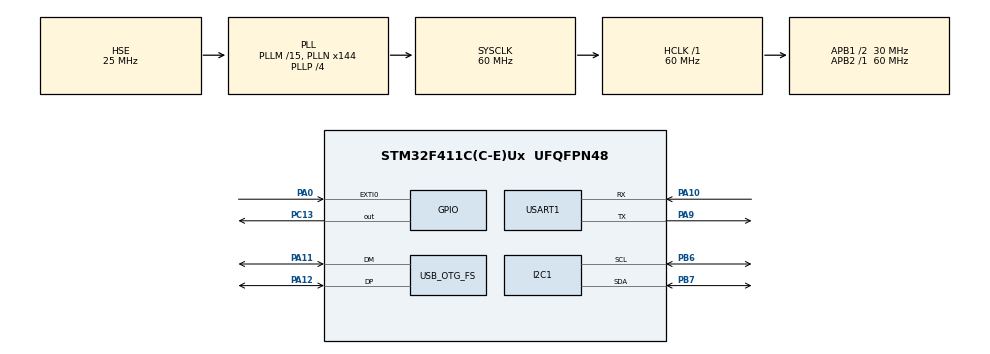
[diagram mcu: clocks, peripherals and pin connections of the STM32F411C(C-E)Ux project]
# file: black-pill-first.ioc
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FREERTOS.Tasks01=defaultTask,24,128,StartDefaultTask,Default,NULL,Dynamic,NULL,NULL
Mcu.Family=STM32F4
Mcu.Name=STM32F411C(C-E)Ux
Mcu.Package=UFQFPN48
NVIC.OTG_FS_IRQn=true\:5\:0\:false\:false\:true\:true\:false\:true\:true
NVIC.PriorityGroup=NVIC_PRIORITYGROUP_4
NVIC.TIM1_UP_TIM10_IRQn=true\:15\:0\:false\:false\:true\:false\:false\:true\:true
NVIC.TimeBase=TIM1_UP_TIM10_IRQn
NVIC.TimeBaseIP=TIM1
PA0-WKUP.GPIO_ModeDefaultEXTI=GPIO_MODE_IT_RISING_FALLING
PA0-WKUP.GPIO_PuPd=GPIO_NOPULL
PA0-WKUP.Signal=GPXTI0
PA10.Mode=Asynchronous
PA10.Signal=USART1_RX
PA11.Mode=Device_Only
PA11.Signal=USB_OTG_FS_DM
PA12.Mode=Device_Only
PA12.Signal=USB_OTG_FS_DP
PA13.Mode=Serial_Wire
PA13.Signal=SYS_JTMS-SWDIO
PA14.Mode=Serial_Wire
PA14.Signal=SYS_JTCK-SWCLK
PA9.Mode=Asynchronous
PA9.Signal=USART1_TX
PB6.Mode=I2C
PB6.Signal=I2C1_SCL
PB7.Mode=I2C
PB7.Signal=I2C1_SDA
PC13-ANTI_TAMP.Signal=GPIO_Output
PH0\ -\ OSC_IN.Mode=HSE-External-Oscillator
PH0\ -\ OSC_IN.Signal=RCC_OSC_IN
PH1\ -\ OSC_OUT.Mode=HSE-External-Oscillator
PH1\ -\ OSC_OUT.Signal=RCC_OSC_OUT
ProjectManager.HeapSize=0x200
ProjectManager.StackSize=0x400
ProjectManager.TargetToolchain=CMake
RCC.48MHZClocksFreq_Value=48000000
RCC.AHBFreq_Value=60000000
RCC.APB1CLKDivider=RCC_HCLK_DIV2
RCC.APB1Freq_Value=30000000
RCC.APB1TimFreq_Value=60000000
RCC.APB2Freq_Value=60000000
RCC.APB2TimFreq_Value=60000000
RCC.CortexFreq_Value=60000000
RCC.HCLKFreq_Value=60000000
RCC.HSE_VALUE=25000000
RCC.HSI_VALUE=16000000
RCC.LSE_VALUE=32768
RCC.PLLM=15
RCC.PLLN=144
RCC.PLLP=RCC_PLLP_DIV4
RCC.PLLQ=5
RCC.SYSCLKFreq_VALUE=60000000
RCC.SYSCLKSource=RCC_SYSCLKSOURCE_PLLCLK
RCC.VCOOutputFreq_Value=240000000
USART1.VirtualMode=VM_ASYNC
USB_DEVICE.CLASS_NAME_FS=CDC
USB_DEVICE.VirtualMode=Cdc
USB_DEVICE.VirtualModeFS=Cdc_FS
USB_OTG_FS.VirtualMode=Device_Only
VP_FREERTOS_VS_CMSIS_V2.Mode=CMSIS_V2
VP_SYS_VS_tim1.Mode=TIM1
VP_USB_DEVICE_VS_USB_DEVICE_CDC_FS.Mode=CDC_FS
board=custom

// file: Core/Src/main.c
/* USER CODE BEGIN Header */
/**
  ******************************************************************************
  * @file           : main.c
  * @brief          : Main program body
  ******************************************************************************
  * @attention
  *
  * Copyright (c) 2026 STMicroelectronics.
  * All rights reserved.
  *
  * This software is licensed under terms that can be found in the LICENSE file
  * in the root directory of this software component.
  * If no LICENSE file comes with this software, it is provided AS-IS.
  *
  ******************************************************************************
  */
/* USER CODE END Header */
#include "main.h"
#include "cmsis_os.h"
#include "i2c.h"
#include "usart.h"
#include "usb_device.h"
#include "gpio.h"

/* USER CODE BEGIN Includes */
#include "app.h"
#include "usbd_cdc_if.h"
#include <string.h>
#include <stdio.h>
/* USER CODE END Includes */

void SystemClock_Config(void);
void MX_FREERTOS_Init(void);

/* USER CODE BEGIN 0 */

int _write(int file, char *ptr, int len) {
    CDC_Transmit_FS((uint8_t*)ptr, len);
    return len;
}

/* USER CODE END 0 */

int main(void)
{

  /* MCU Configuration--------------------------------------------------------*/

  /* Reset of all peripherals, Initializes the Flash interface and the Systick. */
  HAL_Init();

  /* Configure the system clock */
  SystemClock_Config();

  /* Initialize all configured peripherals */
  MX_GPIO_Init();
  MX_I2C1_Init();
  MX_USART1_UART_Init();
  /* USER CODE BEGIN 2 */
  app_start(); // <--- Додайте виклики вашого коду сюди
  /* USER CODE END 2 */

  /* Init scheduler */
  osKernelInitialize();  /* Call init function for freertos objects (in cmsis_os2.c) */
  MX_FREERTOS_Init();

  /* Start scheduler */
  osKernelStart();

  /* We should never get here as control is now taken by the scheduler */

  /* Infinite loop */
  /* USER CODE BEGIN WHILE */

  char msg[64];
  uint16_t count = 0;

  while (1)
  {
    /* USER CODE END WHILE */

    /* USER CODE BEGIN 3 */
    int len = sprintf(msg, "Hello from STM32 USB CDC! Count: %d\r\n", count++);
    CDC_Transmit_FS((uint8_t*)msg, len);

    HAL_Delay(1000); // Затримка 1 секунда

  }
  /* USER CODE END 3 */
}

void SystemClock_Config(void)
{
  RCC_OscInitTypeDef RCC_OscInitStruct = {0};
  RCC_ClkInitTypeDef RCC_ClkInitStruct = {0};

  /** Configure the main internal regulator output voltage
  */
  __HAL_RCC_PWR_CLK_ENABLE();
  __HAL_PWR_VOLTAGESCALING_CONFIG(PWR_REGULATOR_VOLTAGE_SCALE1);

  /** Initializes the RCC Oscillators according to the specified parameters
  * in the RCC_OscInitTypeDef structure.
  */
  RCC_OscInitStruct.OscillatorType = RCC_OSCILLATORTYPE_HSE;
  RCC_OscInitStruct.HSEState = RCC_HSE_ON;
  RCC_OscInitStruct.PLL.PLLState = RCC_PLL_ON;
  RCC_OscInitStruct.PLL.PLLSource = RCC_PLLSOURCE_HSE;
  RCC_OscInitStruct.PLL.PLLM = 15;
  RCC_OscInitStruct.PLL.PLLN = 144;
  RCC_OscInitStruct.PLL.PLLP = RCC_PLLP_DIV4;
  RCC_OscInitStruct.PLL.PLLQ = 5;
  if (HAL_RCC_OscConfig(&RCC_OscInitStruct) != HAL_OK)
  {
    Error_Handler();
  }

  /** Initializes the CPU, AHB and APB buses clocks
  */
  RCC_ClkInitStruct.ClockType = RCC_CLOCKTYPE_HCLK|RCC_CLOCKTYPE_SYSCLK
                              |RCC_CLOCKTYPE_PCLK1|RCC_CLOCKTYPE_PCLK2;
  RCC_ClkInitStruct.SYSCLKSource = RCC_SYSCLKSOURCE_PLLCLK;
  RCC_ClkInitStruct.AHBCLKDivider = RCC_SYSCLK_DIV1;
  RCC_ClkInitStruct.APB1CLKDivider = RCC_HCLK_DIV2;
  RCC_ClkInitStruct.APB2CLKDivider = RCC_HCLK_DIV1;

  if (HAL_RCC_ClockConfig(&RCC_ClkInitStruct, FLASH_LATENCY_1) != HAL_OK)
  {
    Error_Handler();
  }
}

void HAL_TIM_PeriodElapsedCallback(TIM_HandleTypeDef *htim)
{
  if (htim->Instance == TIM1)
  {
    HAL_IncTick();
  }
}

void Error_Handler(void)
{
  __disable_irq();
  while (1)
  {
  }
}
